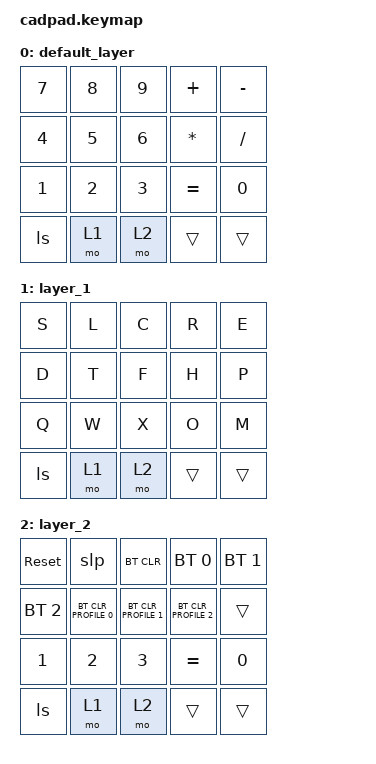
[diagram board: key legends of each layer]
#include <behaviors.dtsi>
#include <dt-bindings/zmk/keys.h>

/ {
    keymap {
        compatible = "zmk,keymap";

        default_layer { // Layer 0: Numbers and Math Functions
            bindings = <
                &kp N7 &kp N8 &kp N9 &kp PLUS  &kp MINUS
                &kp N4 &kp N5 &kp N6 &kp ASTERISK &kp SLASH
                &kp N1 &kp N2 &kp N3 &kp EQUAL &kp N0
                &ls    &mo 1  &mo 2  &trans    &trans
            >;
        };

        layer_1 { // Layer 1: Fusion 360 Command Layer
            bindings = <
                &kp S  &kp L  &kp C  &kp R  &kp E     // Sketch, Line, Circle, Rectangle, Extrude
                &kp D  &kp T  &kp F  &kp H  &kp P     // Dimension, Trim, Fillet, Hole, Project
                &kp Q  &kp W  &kp X  &kp O  &kp M     // Quit sketch, Offset, Explode, Offset, Move
                &ls    &mo 1  &mo 2  &trans &trans
            >;
        };

        layer_2 { // Layer 2: System and Bluetooth Functions
            bindings = <
                &sys_reset &slp        &bt BT_CLR    &bt BT_SEL 0 &bt BT_SEL 1
                &bt BT_SEL 2 &bt BT_CLR_PROFILE 0 &bt BT_CLR_PROFILE 1 &bt BT_CLR_PROFILE 2 &trans
                &kp N1     &kp N2     &kp N3        &kp EQUAL    &kp N0
                &ls        &mo 1      &mo 2         &trans       &trans
            >;
        };
    };
};

